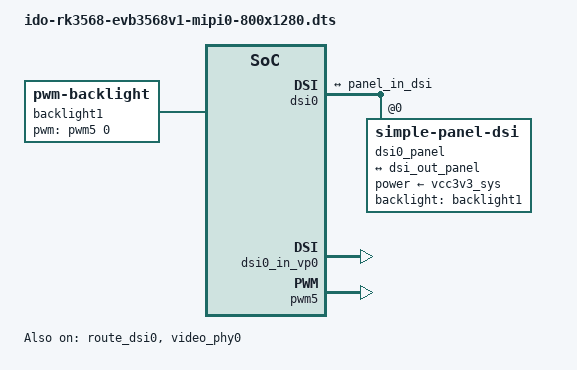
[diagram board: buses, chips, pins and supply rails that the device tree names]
// SPDX-License-Identifier: (GPL-2.0+ OR MIT)
/*
 * Copyright (c) 2020 Rockchip Electronics Co., Ltd.
 *
 */

/dts-v1/;

#include "ido-rk3568-evb3568v1.dts"

/{
	backlight1: backlight1 {
		compatible = "pwm-backlight";
		pwms = <&pwm5 0 25000 0>;
		brightness-levels = <
			  0  20  20  21  21  22  22  23
			 23  24  24  25  25  26  26  27
			 27  28  28  29  29  30  30  31
			 31  32  32  33  33  34  34  35
			 35  36  36  37  37  38  38  39
			 40  41  42  43  44  45  46  47
			 48  49  50  51  52  53  54  55
			 56  57  58  59  60  61  62  63
			 64  65  66  67  68  69  70  71
			 72  73  74  75  76  77  78  79
			 80  81  82  83  84  85  86  87
			 88  89  90  91  92  93  94  95
			 96  97  98  99 100 101 102 103
			104 105 106 107 108 109 110 111
			112 113 114 115 116 117 118 119
			120 121 122 123 124 125 126 127
			128 129 130 131 132 133 134 135
			136 137 138 139 140 141 142 143
			144 145 146 147 148 149 150 151
			152 153 154 155 156 157 158 159
			160 161 162 163 164 165 166 167
			168 169 170 171 172 173 174 175
			176 177 178 179 180 181 182 183
			184 185 186 187 188 189 190 191
			192 193 194 195 196 197 198 199
			200 201 202 203 204 205 206 207
			208 209 210 211 212 213 214 215
			216 217 218 219 220 221 222 223
			224 225 226 227 228 229 230 231
			232 233 234 235 236 237 238 239
			240 241 242 243 244 245 246 247
			248 249 250 251 252 253 254 255
		>;
		default-brightness-level = <200>;
	};
};
/*
 * video_phy0 needs to be enabled
 * when dsi0 is enabled
 */
&dsi0 {
	status = "okay";
	//rockchip,lane-rate = <1000>;
	dsi0_panel: panel@0 {
		status = "okay";
		compatible = "simple-panel-dsi";
		reg = <0>;
		power-supply = <&vcc3v3_sys>;
		backlight = <&backlight1>;
		reset-delay-ms = <60>;
		enable-delay-ms = <60>;
		prepare-delay-ms = <60>;
		unprepare-delay-ms = <60>;
		disable-delay-ms = <60>;
		dsi,flags = <(MIPI_DSI_MODE_VIDEO | MIPI_DSI_MODE_VIDEO_BURST |
			MIPI_DSI_MODE_LPM | MIPI_DSI_MODE_EOT_PACKET)>;
		dsi,format = <MIPI_DSI_FMT_RGB888>;
		dsi,lanes  = <4>;
		panel-init-sequence = [			
				39 00 04 FF 98 81 03 //Page3 command		
				39 00 02 01 00 //GIP_1
				39 00 02 02 00 
				39 00 02 03 73 
				39 00 02 04 00 
				39 00 02 05 00 
				39 00 02 06 08 
				39 00 02 07 00 
				39 00 02 08 00 
				39 00 02 09 00 
				39 00 02 0A 01 
				39 00 02 0B 01 
				39 00 02 0C 00 
				39 00 02 0D 01 
				39 00 02 0E 01 
				39 00 02 0F 00 
				39 00 02 10 00 
				39 00 02 11 00 
				39 00 02 12 00 
				39 00 02 13 1F 
				39 00 02 14 1F 
				39 00 02 15 00 
				39 00 02 16 00 
				39 00 02 17 00 
				39 00 02 18 00 
				39 00 02 19 00 
				39 00 02 1A 00 
				39 00 02 1B 00 
				39 00 02 1C 00 
				39 00 02 1D 00 
				39 00 02 1E 40 
				39 00 02 1F C0 
				39 00 02 20 06 
				39 00 02 21 01 
				39 00 02 22 06 
				39 00 02 23 01 
				39 00 02 24 88 
				39 00 02 25 88 
				39 00 02 26 00 
				39 00 02 27 00 
				39 00 02 28 3B 
				39 00 02 29 03 
				39 00 02 2A 00 
				39 00 02 2B 00 
				39 00 02 2C 00 
				39 00 02 2D 00 
				39 00 02 2E 00 
				39 00 02 2F 00 
				39 00 02 30 00 
				39 00 02 31 00 
				39 00 02 32 00 
				39 00 02 33 00 
				39 00 02 34 00 //GPWR1/2 non overlap time 2.62us     
				39 00 02 35 00 
				39 00 02 36 00 
				39 00 02 37 00 
				39 00 02 38 00 
				39 00 02 39 00 
				39 00 02 3A 00 
				39 00 02 3B 00 
				39 00 02 3C 00 
				39 00 02 3D 00 
				39 00 02 3E 00 
				39 00 02 3F 00 
				39 00 02 40 00 
				39 00 02 41 00 
				39 00 02 42 00 
				39 00 02 43 00 
				39 00 02 44 00 
				
				39 00 02 50 01 //GIP_2
				39 00 02 51 23 
				39 00 02 52 45 
				39 00 02 53 67 
				39 00 02 54 89 
				39 00 02 55 dA // AB
				39 00 02 56 01 
				39 00 02 57 23 
				39 00 02 58 45 
				39 00 02 59 67 
				39 00 02 5A 89 
				39 00 02 5B AB 
				39 00 02 5C CD 
				39 00 02 5D EF 

				39 00 02 5E 00 //GIP_3
				39 00 02 5F 01 
				39 00 02 60 01 
				39 00 02 61 06 
				39 00 02 62 06 
				39 00 02 63 07 
				39 00 02 64 07 
				39 00 02 65 00 
				39 00 02 66 00 
				39 00 02 67 02 
				39 00 02 68 02 
				39 00 02 69 05 
				39 00 02 6A 05 
				39 00 02 6B 02 
				39 00 02 6C 0D 
				39 00 02 6D 0D 
				39 00 02 6E 0C 
				39 00 02 6F 0C 
				39 00 02 70 0F 
				39 00 02 71 0F 
				39 00 02 72 0E 
				39 00 02 73 0E 
				39 00 02 74 02 
				39 00 02 75 01 
				39 00 02 76 01 
				39 00 02 77 06 
				39 00 02 78 06 
				39 00 02 79 07 
				39 00 02 7A 07 
				39 00 02 7B 00 
				39 00 02 7C 00 
				39 00 02 7D 02 
				39 00 02 7E 02 
				39 00 02 7F 05 
				39 00 02 80 05 
				39 00 02 81 02 
				39 00 02 82 0D 
				39 00 02 83 0D 
				39 00 02 84 0C 
				39 00 02 85 0C 
				39 00 02 86 0F 
				39 00 02 87 0F 
				39 00 02 88 0E 
				39 00 02 89 0E 
				39 00 02 8A 02 

				39 00 04 FF 98 81 04 //Page4 command
				39 00 02 3B C0 //ILI4003D sel
				39 00 02 6C 15 //SetVCOREvoltage=1.5V 
				39 00 02 6E 2A //di_pwr_reg=0 for power mode2A//VGH clamp 18V 
				39 00 02 6F 33 //45 //pumping ratio VGH=5x VGL=-3x   
				39 00 02 8D 1B //VGL clamp -10V 
				39 00 02 87 BA //ESD  
				39 00 02 3A 24 //POWER SAVING   
				39 00 02 26 76 
				39 00 02 B2 D1 


				
				39 00 04 FF 98 81 01 //Page1 command 
				39 00 02 22 0A //BGR, SS  
				39 00 02 31 00 //Zigzag type3 inversion ;
				39 00 02 40 53 // ILI4003D sel
				39 00 02 43 66 
				39 00 02 53 40 
				39 00 02 50 87 
				39 00 02 51 82    
				39 00 02 60 15 
				39 00 02 61 01 
				39 00 02 62 0C 
				39 00 02 63 00 

				
				39 00 02 A0 00 // Gamma P 
				39 00 02 A1 13 //VP251
				39 00 02 A2 23 //VP247
				39 00 02 A3 14 //VP243 
				39 00 02 A4 16 //VP239
				39 00 02 A5 29 //VP231
				39 00 02 A6 1E //VP219 
				39 00 02 A7 1D //VP203 
				39 00 02 A8 86 //VP175 
				39 00 02 A9 1E //VP144 
				39 00 02 AA 29 //VP111 
				39 00 02 AB 74 //VP80 
				39 00 02 AC 19 //VP52
				39 00 02 AD 17 //VP36 
				39 00 02 AE 4B //VP24 
				39 00 02 AF 20 //VP16 
				39 00 02 B0 26 //VP12 
				39 00 02 B1 4C //VP8 
				39 00 02 B2 5D //VP4 
				39 00 02 B3 3F //VP0
				
				39 00 02 C0 00 // Gamma N //VN255 GAMMA N
				39 00 02 C1 13 //VN251 
				39 00 02 C2 23 //VN247 
				39 00 02 C3 14 //VN243 
				39 00 02 C4 16 //VN239 
				39 00 02 C5 29 //VN231 
				39 00 02 C6 1E //VN219 
				39 00 02 C7 1D //VN203 
				39 00 02 C8 86 //VN175 
				39 00 02 C9 1E //VN144 
				39 00 02 CA 29 //VN111
				39 00 02 CB 74 //VN80 
				39 00 02 CC 19 //VN52 
				39 00 02 CD 17 //VN36 
				39 00 02 CE 4B //VN24 
				39 00 02 CF 20 //VN16 
				39 00 02 D0 26 //VN12 
				39 00 02 D1 4C //VN8 
				39 00 02 D2 5D //VN4 
				39 00 02 D3 3F //VN0
			
				39 00 04 FF 98 81 00 	//Page0 command 
				39 00 02 35 00 // TE On
				
				05 78 01 11
				05 14 01 29				
			]; 

			panel-exit-sequence = [
							05 00 01 28
							05 78 01 10
			];

		disp_timings0: display-timings {
			native-mode = <&dsi0_timing0>;
			dsi0_timing0: timing0 {
				clock-frequency = <72000000>;
					hactive = <800>;
					vactive = <1280>;
					hback-porch = <120>;
					hfront-porch = <32>;
					vback-porch = <18>;
					vfront-porch = <8>;
					hsync-len = <6>;
					vsync-len = <4>;
					hsync-active = <1>;
					vsync-active = <1>;
					de-active = <0>;
					pixelclk-active = <0>;
			};
		};

		ports {
			#address-cells = <1>;
			#size-cells = <0>;

			port@0 {
				reg = <0>;
				panel_in_dsi: endpoint {
					remote-endpoint = <&dsi_out_panel>;
				};
			};
		};
	};

	ports {
		#address-cells = <1>;
		#size-cells = <0>;

		port@1 {
			reg = <1>;
			dsi_out_panel: endpoint {
				remote-endpoint = <&panel_in_dsi>;
			};
		};
	};
};

&dsi0_in_vp0 {
	status = "okay";
};

&dsi0_in_vp1 {
	status = "disabled";
};

&route_dsi0 {
	status = "okay";
	connect = <&vp1_out_dsi0>;
};

&video_phy0 {
	status = "okay";
};

&backlight1 {
	status = "okay";
};

&pwm5 {
	status = "okay";
};

&hdmi {
	status = "disabled";
};

&hdmi_in_vp0 {
	status = "disabled";
};

&hdmi_in_vp1 {
	status = "disabled";
};

&hdmi_sound {
	status = "disabled";
};
